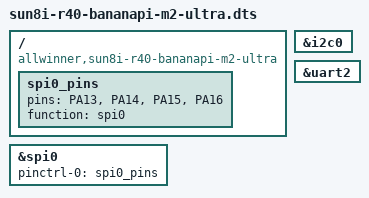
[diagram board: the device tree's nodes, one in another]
/dts-v1/;
/plugin/;

/ {
    compatible = "allwinner,sun8i-r40-bananapi-m2-ultra";

    fragment@0 {
        target-path = "/";
        __overlay__ {
            spi0_pins: spi0_pins {
                pins = "PA13", "PA14", "PA15", "PA16";
                function = "spi0";
            };
        };
    };

    fragment@1 {
        target = <&spi0>;
        __overlay__ {
            status = "okay";
            pinctrl-names = "default";
            pinctrl-0 = <&spi0_pins>;
        };
    };

    fragment@2 {
        target = <&i2c0>;
        __overlay__ {
            status = "okay";
        };
    };

    fragment@3 {
        target = <&uart2>;
        __overlay__ {
            status = "okay";
        };
    };
};
